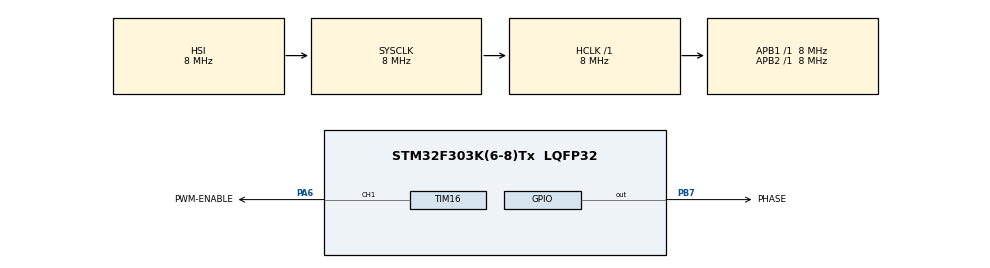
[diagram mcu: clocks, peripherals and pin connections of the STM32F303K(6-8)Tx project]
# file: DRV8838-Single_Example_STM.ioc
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Mcu.Family=STM32F3
Mcu.Name=STM32F303K(6-8)Tx
Mcu.Package=LQFP32
NVIC.PriorityGroup=NVIC_PRIORITYGROUP_4
PA6.GPIO_Label=PWM-ENABLE
PA6.Signal=S_TIM16_CH1
PB7.GPIO_Label=PHASE
PB7.Signal=GPIO_Output
ProjectManager.HeapSize=0x200
ProjectManager.StackSize=0x400
ProjectManager.TargetToolchain=TrueSTUDIO
RCC.AHBFreq_Value=8000000
RCC.APB1Freq_Value=8000000
RCC.APB2Freq_Value=8000000
RCC.CortexFreq_Value=8000000
RCC.HSE_VALUE=8000000
RCC.HSI_VALUE=8000000
RCC.SYSCLKFreq_VALUE=8000000
SH.S_TIM16_CH1.0=TIM16_CH1,PWM Generation1 CH1
TIM16.Channel=TIM_CHANNEL_1
TIM16.Period=100
TIM16.Prescaler=8
TIM16.Pulse=50
VP_TIM16_VS_ClockSourceINT.Mode=Enable_Timer
board=custom

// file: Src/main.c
/* USER CODE BEGIN Header */
/**
  ******************************************************************************
  * @file           : main.c
  * @brief          : Main program body
  ******************************************************************************
  * @attention
  *
  * <h2><center>&copy; Copyright (c) 2019 STMicroelectronics.
  * All rights reserved.</center></h2>
  *
  * This software component is licensed by ST under BSD 3-Clause license,
  * the "License"; You may not use this file except in compliance with the
  * License. You may obtain a copy of the License at:
  *                        opensource.org/licenses/BSD-3-Clause
  *
  ******************************************************************************
  */
/* USER CODE END Header */

#include "main.h"

TIM_HandleTypeDef htim16;

void SystemClock_Config(void);
static void MX_GPIO_Init(void);
static void MX_TIM16_Init(void);

int main(void)
{

  /* MCU Configuration--------------------------------------------------------*/

  /* Reset of all peripherals, Initializes the Flash interface and the Systick. */
  HAL_Init();

  /* Configure the system clock */
  SystemClock_Config();

  /* Initialize all configured peripherals */
  MX_GPIO_Init();
  MX_TIM16_Init();
  /* USER CODE BEGIN 2 */
  // iniciar o PWM
  HAL_TIM_PWM_Start(&htim16, TIM_CHANNEL_1);

  // declarar as variАveis de uso
  short signed int duty, phase;
  phase=1;
  /* USER CODE END 2 */

  /* Infinite loop */
  while (1)
  {

    /* USER CODE BEGIN 3 */

	  HAL_GPIO_WritePin(GPIOB, PHASE_Pin, (GPIO_PinState)phase);
	  for(duty=0; duty<(uint16_t)htim16.Init.Period; duty+=10)
	  {
		  htim16.Instance->CCR1 = (uint32_t)duty;
		  HAL_Delay(1000);
	  }
	  HAL_Delay(1000);
	  for(; duty>=0; duty-=10)
	  {
		  htim16.Instance->CCR1 = (uint32_t)duty;
		  HAL_Delay(1000);
	  }
	  HAL_Delay(1000);

	  if(phase==1)
		  phase=0;
	  else
		  phase=1;
  }
  /* USER CODE END 3 */
}

void SystemClock_Config(void)
{
  RCC_OscInitTypeDef RCC_OscInitStruct = {0};
  RCC_ClkInitTypeDef RCC_ClkInitStruct = {0};

  /** Initializes the CPU, AHB and APB busses clocks
  */
  RCC_OscInitStruct.OscillatorType = RCC_OSCILLATORTYPE_HSI;
  RCC_OscInitStruct.HSIState = RCC_HSI_ON;
  RCC_OscInitStruct.HSICalibrationValue = RCC_HSICALIBRATION_DEFAULT;
  RCC_OscInitStruct.PLL.PLLState = RCC_PLL_NONE;
  if (HAL_RCC_OscConfig(&RCC_OscInitStruct) != HAL_OK)
  {
    Error_Handler();
  }
  /** Initializes the CPU, AHB and APB busses clocks
  */
  RCC_ClkInitStruct.ClockType = RCC_CLOCKTYPE_HCLK|RCC_CLOCKTYPE_SYSCLK
                              |RCC_CLOCKTYPE_PCLK1|RCC_CLOCKTYPE_PCLK2;
  RCC_ClkInitStruct.SYSCLKSource = RCC_SYSCLKSOURCE_HSI;
  RCC_ClkInitStruct.AHBCLKDivider = RCC_SYSCLK_DIV1;
  RCC_ClkInitStruct.APB1CLKDivider = RCC_HCLK_DIV1;
  RCC_ClkInitStruct.APB2CLKDivider = RCC_HCLK_DIV1;

  if (HAL_RCC_ClockConfig(&RCC_ClkInitStruct, FLASH_LATENCY_0) != HAL_OK)
  {
    Error_Handler();
  }
}

static void MX_TIM16_Init(void)
{

  TIM_OC_InitTypeDef sConfigOC = {0};
  TIM_BreakDeadTimeConfigTypeDef sBreakDeadTimeConfig = {0};

  htim16.Instance = TIM16;
  htim16.Init.Prescaler = 8;
  htim16.Init.CounterMode = TIM_COUNTERMODE_UP;
  htim16.Init.Period = 100;
  htim16.Init.ClockDivision = TIM_CLOCKDIVISION_DIV1;
  htim16.Init.RepetitionCounter = 0;
  htim16.Init.AutoReloadPreload = TIM_AUTORELOAD_PRELOAD_DISABLE;
  if (HAL_TIM_Base_Init(&htim16) != HAL_OK)
  {
    Error_Handler();
  }
  if (HAL_TIM_PWM_Init(&htim16) != HAL_OK)
  {
    Error_Handler();
  }
  sConfigOC.OCMode = TIM_OCMODE_PWM1;
  sConfigOC.Pulse = 50;
  sConfigOC.OCPolarity = TIM_OCPOLARITY_HIGH;
  sConfigOC.OCNPolarity = TIM_OCNPOLARITY_HIGH;
  sConfigOC.OCFastMode = TIM_OCFAST_DISABLE;
  sConfigOC.OCIdleState = TIM_OCIDLESTATE_RESET;
  sConfigOC.OCNIdleState = TIM_OCNIDLESTATE_RESET;
  if (HAL_TIM_PWM_ConfigChannel(&htim16, &sConfigOC, TIM_CHANNEL_1) != HAL_OK)
  {
    Error_Handler();
  }
  sBreakDeadTimeConfig.OffStateRunMode = TIM_OSSR_DISABLE;
  sBreakDeadTimeConfig.OffStateIDLEMode = TIM_OSSI_DISABLE;
  sBreakDeadTimeConfig.LockLevel = TIM_LOCKLEVEL_OFF;
  sBreakDeadTimeConfig.DeadTime = 0;
  sBreakDeadTimeConfig.BreakState = TIM_BREAK_DISABLE;
  sBreakDeadTimeConfig.BreakPolarity = TIM_BREAKPOLARITY_HIGH;
  sBreakDeadTimeConfig.BreakFilter = 0;
  sBreakDeadTimeConfig.AutomaticOutput = TIM_AUTOMATICOUTPUT_DISABLE;
  if (HAL_TIMEx_ConfigBreakDeadTime(&htim16, &sBreakDeadTimeConfig) != HAL_OK)
  {
    Error_Handler();
  }
  HAL_TIM_MspPostInit(&htim16);

}

static void MX_GPIO_Init(void)
{
  GPIO_InitTypeDef GPIO_InitStruct = {0};

  /* GPIO Ports Clock Enable */
  __HAL_RCC_GPIOA_CLK_ENABLE();
  __HAL_RCC_GPIOB_CLK_ENABLE();

  /*Configure GPIO pin Output Level */
  HAL_GPIO_WritePin(PHASE_GPIO_Port, PHASE_Pin, GPIO_PIN_RESET);

  /*Configure GPIO pin : PHASE_Pin */
  GPIO_InitStruct.Pin = PHASE_Pin;
  GPIO_InitStruct.Mode = GPIO_MODE_OUTPUT_PP;
  GPIO_InitStruct.Pull = GPIO_NOPULL;
  GPIO_InitStruct.Speed = GPIO_SPEED_FREQ_LOW;
  HAL_GPIO_Init(PHASE_GPIO_Port, &GPIO_InitStruct);

}

void Error_Handler(void)
{
}

/************************ (C) COPYRIGHT STMicroelectronics *****END OF FILE****/
